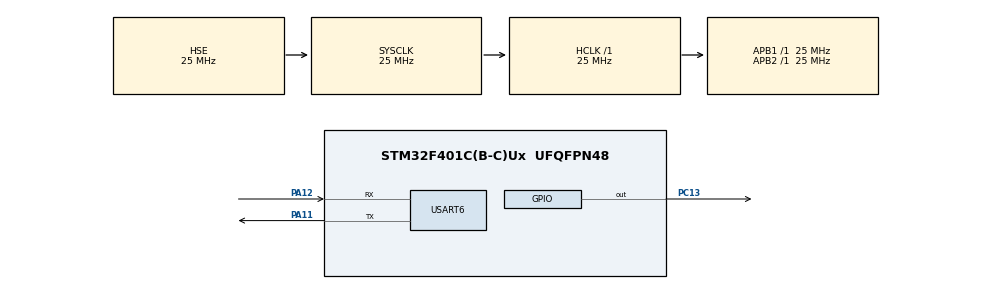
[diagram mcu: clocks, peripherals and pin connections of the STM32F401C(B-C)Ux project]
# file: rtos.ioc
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FREERTOS.Tasks01=defaultTask,24,128,StartDefaultTask,Default,NULL,Dynamic,NULL,NULL
Mcu.Family=STM32F4
Mcu.Name=STM32F401C(B-C)Ux
Mcu.Package=UFQFPN48
NVIC.PriorityGroup=NVIC_PRIORITYGROUP_4
NVIC.TIM5_IRQn=true\:15\:0\:false\:false\:true\:false\:false\:true\:true
NVIC.TimeBase=TIM5_IRQn
NVIC.TimeBaseIP=TIM5
PA11.Mode=Asynchronous
PA11.Signal=USART6_TX
PA12.Mode=Asynchronous
PA12.Signal=USART6_RX
PA13.Mode=Trace_Asynchronous_SW
PA13.Signal=SYS_JTMS-SWDIO
PA14.Mode=Trace_Asynchronous_SW
PA14.Signal=SYS_JTCK-SWCLK
PA9.Signal=USART1_TX
PB3.Mode=Trace_Asynchronous_SW
PB3.Signal=SYS_JTDO-SWO
PC13-ANTI_TAMP.PinState=GPIO_PIN_RESET
PC13-ANTI_TAMP.Signal=GPIO_Output
PH0\ -\ OSC_IN.Mode=HSE-External-Oscillator
PH0\ -\ OSC_IN.Signal=RCC_OSC_IN
PH1\ -\ OSC_OUT.Mode=HSE-External-Oscillator
PH1\ -\ OSC_OUT.Signal=RCC_OSC_OUT
ProjectManager.HeapSize=0x200
ProjectManager.StackSize=0x400
ProjectManager.TargetToolchain=STM32CubeIDE
RCC.48MHZClocksFreq_Value=75000000
RCC.AHBFreq_Value=25000000
RCC.APB1Freq_Value=25000000
RCC.APB1TimFreq_Value=25000000
RCC.APB2Freq_Value=25000000
RCC.APB2TimFreq_Value=25000000
RCC.CortexFreq_Value=25000000
RCC.HCLKFreq_Value=25000000
RCC.HSE_VALUE=25000000
RCC.HSI_VALUE=16000000
RCC.LSE_VALUE=32768
RCC.PLLSourceVirtual=RCC_PLLSOURCE_HSE
RCC.SYSCLKFreq_VALUE=25000000
RCC.SYSCLKSource=RCC_SYSCLKSOURCE_HSE
RCC.VCOOutputFreq_Value=300000000
USART6.VirtualMode=VM_ASYNC
VP_FREERTOS_VS_CMSIS_V2.Mode=CMSIS_V2
VP_SYS_VS_tim5.Mode=TIM5
board=custom

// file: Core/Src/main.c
/* USER CODE BEGIN Header */
/**
  ******************************************************************************
  * @file           : main.c
  * @brief          : Main program body
  ******************************************************************************
  * @attention
  *
  * Copyright (c) 2024 STMicroelectronics.
  * All rights reserved.
  *
  * This software is licensed under terms that can be found in the LICENSE file
  * in the root directory of this software component.
  * If no LICENSE file comes with this software, it is provided AS-IS.
  *
  ******************************************************************************
  */
/* USER CODE END Header */
#include "main.h"
#include "cmsis_os.h"

UART_HandleTypeDef huart6;

/* Definitions for defaultTask */
osThreadId_t defaultTaskHandle;
const osThreadAttr_t defaultTask_attributes = {
  .name = "defaultTask",
  .stack_size = 128 * 4,
  .priority = (osPriority_t) osPriorityNormal,
};

void SystemClock_Config(void);
static void MX_GPIO_Init(void);
static void MX_USART6_UART_Init(void);
void StartDefaultTask(void *argument);

/* USER CODE BEGIN PFP */
void Task_action(char message);

/* USER CODE END PFP */

int main(void)
{

  /* MCU Configuration--------------------------------------------------------*/

  /* Reset of all peripherals, Initializes the Flash interface and the Systick. */
  HAL_Init();

  /* Configure the system clock */
  SystemClock_Config();

  /* Initialize all configured peripherals */
  MX_GPIO_Init();
  MX_USART6_UART_Init();

  /* Init scheduler */
  osKernelInitialize();

  /* Create the thread(s) */
  /* creation of defaultTask */
  defaultTaskHandle = osThreadNew(StartDefaultTask, NULL, &defaultTask_attributes);

  /* Start scheduler */
  osKernelStart();

  /* We should never get here as control is now taken by the scheduler */

  /* Infinite loop */
  while (1)
  {

  }
}

void SystemClock_Config(void)
{
  RCC_OscInitTypeDef RCC_OscInitStruct = {0};
  RCC_ClkInitTypeDef RCC_ClkInitStruct = {0};

  /** Configure the main internal regulator output voltage
  */
  __HAL_RCC_PWR_CLK_ENABLE();
  __HAL_PWR_VOLTAGESCALING_CONFIG(PWR_REGULATOR_VOLTAGE_SCALE2);

  /** Initializes the RCC Oscillators according to the specified parameters
  * in the RCC_OscInitTypeDef structure.
  */
  RCC_OscInitStruct.OscillatorType = RCC_OSCILLATORTYPE_HSE;
  RCC_OscInitStruct.HSEState = RCC_HSE_ON;
  RCC_OscInitStruct.PLL.PLLState = RCC_PLL_NONE;
  if (HAL_RCC_OscConfig(&RCC_OscInitStruct) != HAL_OK)
  {
    Error_Handler();
  }

  /** Initializes the CPU, AHB and APB buses clocks
  */
  RCC_ClkInitStruct.ClockType = RCC_CLOCKTYPE_HCLK|RCC_CLOCKTYPE_SYSCLK
                              |RCC_CLOCKTYPE_PCLK1|RCC_CLOCKTYPE_PCLK2;
  RCC_ClkInitStruct.SYSCLKSource = RCC_SYSCLKSOURCE_HSE;
  RCC_ClkInitStruct.AHBCLKDivider = RCC_SYSCLK_DIV1;
  RCC_ClkInitStruct.APB1CLKDivider = RCC_HCLK_DIV1;
  RCC_ClkInitStruct.APB2CLKDivider = RCC_HCLK_DIV1;

  if (HAL_RCC_ClockConfig(&RCC_ClkInitStruct, FLASH_LATENCY_0) != HAL_OK)
  {
    Error_Handler();
  }
}

static void MX_USART6_UART_Init(void)
{

  huart6.Instance = USART6;
  huart6.Init.BaudRate = 115200;
  huart6.Init.WordLength = UART_WORDLENGTH_8B;
  huart6.Init.StopBits = UART_STOPBITS_1;
  huart6.Init.Parity = UART_PARITY_NONE;
  huart6.Init.Mode = UART_MODE_TX_RX;
  huart6.Init.HwFlowCtl = UART_HWCONTROL_NONE;
  huart6.Init.OverSampling = UART_OVERSAMPLING_16;
  if (HAL_UART_Init(&huart6) != HAL_OK)
  {
    Error_Handler();
  }

}

static void MX_GPIO_Init(void)
{
  GPIO_InitTypeDef GPIO_InitStruct = {0};

  /* GPIO Ports Clock Enable */
  __HAL_RCC_GPIOC_CLK_ENABLE();
  __HAL_RCC_GPIOH_CLK_ENABLE();
  __HAL_RCC_GPIOA_CLK_ENABLE();
  __HAL_RCC_GPIOB_CLK_ENABLE();

  /*Configure GPIO pin Output Level */
  HAL_GPIO_WritePin(GPIOC, GPIO_PIN_13, GPIO_PIN_RESET);

  /*Configure GPIO pin : PC13 */
  GPIO_InitStruct.Pin = GPIO_PIN_13;
  GPIO_InitStruct.Mode = GPIO_MODE_OUTPUT_PP;
  GPIO_InitStruct.Pull = GPIO_NOPULL;
  GPIO_InitStruct.Speed = GPIO_SPEED_FREQ_LOW;
  HAL_GPIO_Init(GPIOC, &GPIO_InitStruct);

  /*Configure GPIO pin : PA9 */
  GPIO_InitStruct.Pin = GPIO_PIN_9;
  GPIO_InitStruct.Mode = GPIO_MODE_AF_PP;
  GPIO_InitStruct.Pull = GPIO_NOPULL;
  GPIO_InitStruct.Speed = GPIO_SPEED_FREQ_VERY_HIGH;
  GPIO_InitStruct.Alternate = GPIO_AF7_USART1;
  HAL_GPIO_Init(GPIOA, &GPIO_InitStruct);

}

/* USER CODE BEGIN 4 */

void Task_action(char message){
	ITM_SendChar(message);
	ITM_SendChar('\n');

}

/* USER CODE END 4 */

void StartDefaultTask(void *argument)
{
  /* USER CODE BEGIN 5 */
  /* Infinite loop */
  for(;;)
  {
	  Task_action('H');
	HAL_GPIO_TogglePin(GPIOC,GPIO_PIN_13);
    osDelay(500);
  }
  /* USER CODE END 5 */
}

void HAL_TIM_PeriodElapsedCallback(TIM_HandleTypeDef *htim)
{
  if (htim->Instance == TIM5) {
    HAL_IncTick();
  }
}

void Error_Handler(void)
{
  __disable_irq();
  while (1)
  {
  }
}
